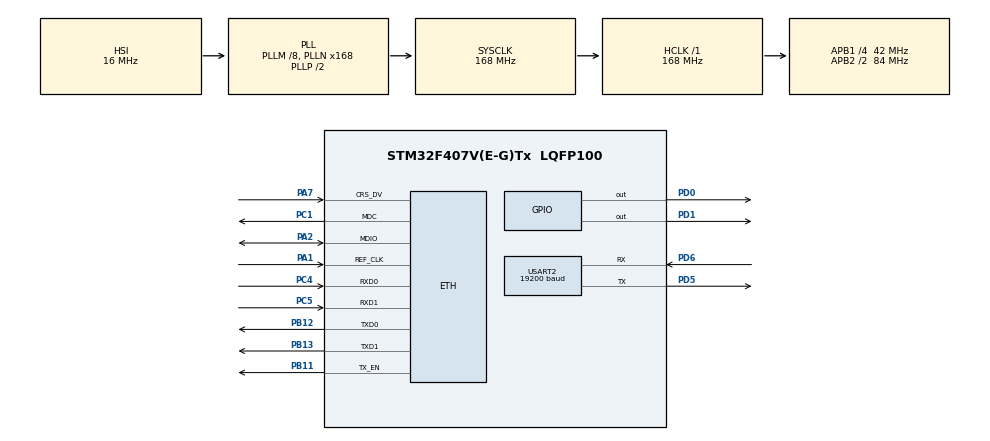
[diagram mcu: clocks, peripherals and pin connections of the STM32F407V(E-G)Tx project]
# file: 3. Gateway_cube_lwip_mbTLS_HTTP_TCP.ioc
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ETH.AutoNegotiation=ETH_AUTONEGOTIATION_DISABLE
ETH.MediaInterface=ETH_MEDIA_INTERFACE_RMII
FREERTOS.INCLUDE_pcTaskGetTaskName=1
FREERTOS.INCLUDE_xSemaphoreGetMutexHolder=1
FREERTOS.INCLUDE_xTaskAbortDelay=1
FREERTOS.INCLUDE_xTaskGetCurrentTaskHandle=1
FREERTOS.Tasks01=defaultTask,0,128,StartDefaultTask,Default,NULL
FREERTOS.configCHECK_FOR_STACK_OVERFLOW=0
FREERTOS.configUSE_MALLOC_FAILED_HOOK=1
LWIP.CHECKSUM_BY_HARDWARE=1
LWIP.GATEWAY_ADDRESS=192.168.002.001
LWIP.HTTPD_MAX_RETRIES=6
LWIP.HTTPD_SERVER_AGENT="RS485-ETH-WS-HVC"
LWIP.HTTPD_USE_CUSTOM_FSDATA=1
LWIP.IP_ADDRESS=192.168.002.020
LWIP.LWIP_DHCP=0
LWIP.LWIP_HTTPD=1
LWIP.LWIP_HTTPD_CGI=1
LWIP.LWIP_HTTPD_SSI=1
LWIP.LWIP_HTTPD_SUPPORT_POST=1
LWIP.MEM_SIZE=20000
LWIP.NETMASK_ADDRESS=255.255.255.000
LWIP.Version=v2.0.3_Cube
Mcu.Family=STM32F4
Mcu.Name=STM32F407V(E-G)Tx
Mcu.Package=LQFP100
NVIC.ETH_IRQn=true\:5\:0\:false\:false\:true\:true\:false
NVIC.PriorityGroup=NVIC_PRIORITYGROUP_4
NVIC.TIM6_DAC_IRQn=true\:0\:0\:false\:false\:true\:false\:false
NVIC.TimeBase=TIM6_DAC_IRQn
NVIC.TimeBaseIP=TIM6
NVIC.USART2_IRQn=true\:5\:0\:false\:false\:true\:true\:true
PA1.Mode=RMII
PA1.Signal=ETH_REF_CLK
PA13.Mode=Serial_Wire
PA13.Signal=SYS_JTMS-SWDIO
PA14.Mode=Serial_Wire
PA14.Signal=SYS_JTCK-SWCLK
PA2.Mode=RMII
PA2.Signal=ETH_MDIO
PA7.Mode=RMII
PA7.Signal=ETH_CRS_DV
PB11.Mode=RMII
PB11.Signal=ETH_TX_EN
PB12.Mode=RMII
PB12.Signal=ETH_TXD0
PB13.Mode=RMII
PB13.Signal=ETH_TXD1
PC1.Mode=RMII
PC1.Signal=ETH_MDC
PC4.Mode=RMII
PC4.Signal=ETH_RXD0
PC5.Mode=RMII
PC5.Signal=ETH_RXD1
PD0.Signal=GPIO_Output
PD1.Signal=GPIO_Output
PD5.Mode=Asynchronous
PD5.Signal=USART2_TX
PD6.Mode=Asynchronous
PD6.Signal=USART2_RX
PH0-OSC_IN.Mode=HSE-External-Oscillator
PH0-OSC_IN.Signal=RCC_OSC_IN
PH1-OSC_OUT.Mode=HSE-External-Oscillator
PH1-OSC_OUT.Signal=RCC_OSC_OUT
ProjectManager.HeapSize=0x200
ProjectManager.StackSize=0x400
ProjectManager.TargetToolchain=MDK-ARM V5
RCC.48MHZClocksFreq_Value=48000000
RCC.AHBFreq_Value=168000000
RCC.APB1CLKDivider=RCC_HCLK_DIV4
RCC.APB1Freq_Value=42000000
RCC.APB1TimFreq_Value=84000000
RCC.APB2CLKDivider=RCC_HCLK_DIV2
RCC.APB2Freq_Value=84000000
RCC.APB2TimFreq_Value=168000000
RCC.CortexFreq_Value=168000000
RCC.HCLKFreq_Value=168000000
RCC.HSE_VALUE=8000000
RCC.HSI_VALUE=16000000
RCC.LSE_VALUE=32768
RCC.PLLM=8
RCC.PLLN=168
RCC.PLLQ=7
RCC.SYSCLKFreq_VALUE=168000000
RCC.SYSCLKSource=RCC_SYSCLKSOURCE_PLLCLK
RCC.VCOOutputFreq_Value=336000000
USART2.BaudRate=19200
USART2.VirtualMode=VM_ASYNC
VP_CRC_VS_CRC.Mode=CRC_Activate
VP_FREERTOS_VS_ENABLE.Mode=Enabled
VP_LWIP_VS_Enabled.Mode=Enabled
VP_MBEDTLS_VS_MBEDTLS.Mode=Enabled
VP_RNG_VS_RNG.Mode=RNG_Activate
VP_SYS_VS_tim6.Mode=TIM6
board=custom

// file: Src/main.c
/* USER CODE BEGIN Header */
/**
  ******************************************************************************
  * @file           : main.c
  * @brief          : Main program body
  ******************************************************************************
  * This notice applies to any and all portions of this file
  * that are not between comment pairs USER CODE BEGIN and
  * USER CODE END. Other portions of this file, whether
  * inserted by the user or by software development tools
  * are owned by their respective copyright owners.
  *
  * Copyright (c) 2020 STMicroelectronics International N.V.
  * All rights reserved.
  *
  * Redistribution and use in source and binary forms, with or without
  * modification, are permitted, provided that the following conditions are met:
  *
  * 1. Redistribution of source code must retain the above copyright notice,
  *    this list of conditions and the following disclaimer.
  * 2. Redistributions in binary form must reproduce the above copyright notice,
  *    this list of conditions and the following disclaimer in the documentation
  *    and/or other materials provided with the distribution.
  * 3. Neither the name of STMicroelectronics nor the names of other
  *    contributors to this software may be used to endorse or promote products
  *    derived from this software without specific written permission.
  * 4. This software, including modifications and/or derivative works of this
  *    software, must execute solely and exclusively on microcontroller or
  *    microprocessor devices manufactured by or for STMicroelectronics.
  * 5. Redistribution and use of this software other than as permitted under
  *    this license is void and will automatically terminate your rights under
  *    this license.
  *
  * THIS SOFTWARE IS PROVIDED BY STMICROELECTRONICS AND CONTRIBUTORS "AS IS"
  * AND ANY EXPRESS, IMPLIED OR STATUTORY WARRANTIES, INCLUDING, BUT NOT
  * LIMITED TO, THE IMPLIED WARRANTIES OF MERCHANTABILITY, FITNESS FOR A
  * PARTICULAR PURPOSE AND NON-INFRINGEMENT OF THIRD PARTY INTELLECTUAL PROPERTY
  * RIGHTS ARE DISCLAIMED TO THE FULLEST EXTENT PERMITTED BY LAW. IN NO EVENT
  * SHALL STMICROELECTRONICS OR CONTRIBUTORS BE LIABLE FOR ANY DIRECT, INDIRECT,
  * INCIDENTAL, SPECIAL, EXEMPLARY, OR CONSEQUENTIAL DAMAGES (INCLUDING, BUT NOT
  * LIMITED TO, PROCUREMENT OF SUBSTITUTE GOODS OR SERVICES; LOSS OF USE, DATA,
  * OR PROFITS; OR BUSINESS INTERRUPTION) HOWEVER CAUSED AND ON ANY THEORY OF
  * LIABILITY, WHETHER IN CONTRACT, STRICT LIABILITY, OR TORT (INCLUDING
  * NEGLIGENCE OR OTHERWISE) ARISING IN ANY WAY OUT OF THE USE OF THIS SOFTWARE,
  * EVEN IF ADVISED OF THE POSSIBILITY OF SUCH DAMAGE.
  *
  ******************************************************************************
  */
/* USER CODE END Header */

#include "main.h"
#include "cmsis_os.h"
#include "mbedtls.h"
#include "app_config.h"

/* USER CODE BEGIN PTD */
void Led_Handler(void const * para);
/* USER CODE END PTD */

CRC_HandleTypeDef hcrc;

RNG_HandleTypeDef hrng;

UART_HandleTypeDef huart2;

osThreadId defaultTaskHandle;

void SystemClock_Config(void);
static void MX_GPIO_Init(void);
void MX_RNG_Init(void);
void MX_CRC_Init(void);
void MX_USART2_UART_Init(void);
void StartDefaultTask(void const * argument);

int main(void)
{

  /* MCU Configuration--------------------------------------------------------*/

  /* Reset of all peripherals, Initializes the Flash interface and the Systick. */
  HAL_Init();

  /* Configure the system clock */
  SystemClock_Config();

  /* Initialize all configured peripherals */
  MX_GPIO_Init();
  MX_RNG_Init();
  MX_CRC_Init();
  MX_USART2_UART_Init();
  /* USER CODE BEGIN 2 */

	printf("\r\nStart");

  /* USER CODE END 2 */

  /* Create the thread(s) */
  /* definition and creation of defaultTask */
  osThreadDef(defaultTask, StartDefaultTask, osPriorityNormal, 0, configMINIMAL_STACK_SIZE);
  defaultTaskHandle = osThreadCreate(osThread(defaultTask), NULL);

  /* Start scheduler */
  osKernelStart();

  /* We should never get here as control is now taken by the scheduler */

  /* Infinite loop */
  while (1)
  {

  }
}

void SystemClock_Config(void)
{
  RCC_OscInitTypeDef RCC_OscInitStruct = {0};
  RCC_ClkInitTypeDef RCC_ClkInitStruct = {0};

  /**Configure the main internal regulator output voltage
  */
  __HAL_RCC_PWR_CLK_ENABLE();
  __HAL_PWR_VOLTAGESCALING_CONFIG(PWR_REGULATOR_VOLTAGE_SCALE1);
  /**Initializes the CPU, AHB and APB busses clocks
  */
  RCC_OscInitStruct.OscillatorType = RCC_OSCILLATORTYPE_HSI;
  RCC_OscInitStruct.HSIState = RCC_HSI_ON;
  RCC_OscInitStruct.HSICalibrationValue = RCC_HSICALIBRATION_DEFAULT;
  RCC_OscInitStruct.PLL.PLLState = RCC_PLL_ON;
  RCC_OscInitStruct.PLL.PLLSource = RCC_PLLSOURCE_HSI;
  RCC_OscInitStruct.PLL.PLLM = 8;
  RCC_OscInitStruct.PLL.PLLN = 168;
  RCC_OscInitStruct.PLL.PLLP = RCC_PLLP_DIV2;
  RCC_OscInitStruct.PLL.PLLQ = 7;
  if (HAL_RCC_OscConfig(&RCC_OscInitStruct) != HAL_OK)
  {
    Error_Handler();
  }
  /**Initializes the CPU, AHB and APB busses clocks
  */
  RCC_ClkInitStruct.ClockType = RCC_CLOCKTYPE_HCLK|RCC_CLOCKTYPE_SYSCLK
                              |RCC_CLOCKTYPE_PCLK1|RCC_CLOCKTYPE_PCLK2;
  RCC_ClkInitStruct.SYSCLKSource = RCC_SYSCLKSOURCE_PLLCLK;
  RCC_ClkInitStruct.AHBCLKDivider = RCC_SYSCLK_DIV1;
  RCC_ClkInitStruct.APB1CLKDivider = RCC_HCLK_DIV4;
  RCC_ClkInitStruct.APB2CLKDivider = RCC_HCLK_DIV2;

  if (HAL_RCC_ClockConfig(&RCC_ClkInitStruct, FLASH_LATENCY_5) != HAL_OK)
  {
    Error_Handler();
  }
}

void MX_CRC_Init(void)
{

  hcrc.Instance = CRC;
  if (HAL_CRC_Init(&hcrc) != HAL_OK)
  {
    Error_Handler();
  }

}

void MX_RNG_Init(void)
{

  hrng.Instance = RNG;
  if (HAL_RNG_Init(&hrng) != HAL_OK)
  {
    Error_Handler();
  }

}

void MX_USART2_UART_Init(void)
{

  huart2.Instance = USART2;
  huart2.Init.BaudRate = 19200;
  huart2.Init.WordLength = UART_WORDLENGTH_8B;
  huart2.Init.StopBits = UART_STOPBITS_1;
  huart2.Init.Parity = UART_PARITY_NONE;
  huart2.Init.Mode = UART_MODE_TX_RX;
  huart2.Init.HwFlowCtl = UART_HWCONTROL_NONE;
  huart2.Init.OverSampling = UART_OVERSAMPLING_16;
  if (HAL_UART_Init(&huart2) != HAL_OK)
  {
    Error_Handler();
  }

}
//

static void MX_GPIO_Init(void)
{
  GPIO_InitTypeDef GPIO_InitStruct = {0};

  /* GPIO Ports Clock Enable */
  __HAL_RCC_GPIOH_CLK_ENABLE();
  __HAL_RCC_GPIOC_CLK_ENABLE();
  __HAL_RCC_GPIOA_CLK_ENABLE();
  __HAL_RCC_GPIOB_CLK_ENABLE();
  __HAL_RCC_GPIOD_CLK_ENABLE();

  /*Configure GPIO pin Output Level */
  HAL_GPIO_WritePin(GPIOD, GPIO_PIN_0|GPIO_PIN_1, GPIO_PIN_RESET);

  /*Configure GPIO pins : PD0 PD1 */
  GPIO_InitStruct.Pin = GPIO_PIN_0|GPIO_PIN_1;
  GPIO_InitStruct.Mode = GPIO_MODE_OUTPUT_PP;
  GPIO_InitStruct.Pull = GPIO_NOPULL;
  GPIO_InitStruct.Speed = GPIO_SPEED_FREQ_LOW;
  HAL_GPIO_Init(GPIOD, &GPIO_InitStruct);

}

void StartDefaultTask(void const * argument)
{
  /* MX_LWIP_Init() is generated within mbedtls_net_init() function in net_cockets.c file */
  /* Up to user to call mbedtls_net_init() function in MBEDTLS initialization step */

  /* Up to user define the empty MX_MBEDTLS_Init() function located in mbedtls.c file */
  MX_MBEDTLS_Init();

	osThreadDef(LedThread, Led_Handler, osPriorityLow, 0, 16);
  osThreadCreate (osThread(LedThread), NULL);

	osThreadDef(Server, SSL_Server, osPriorityHigh, 0, configMINIMAL_STACK_SIZE*20);
  osThreadCreate (osThread(Server), NULL);

  /* USER CODE BEGIN 5 */
  /* Infinite loop */
  for(;;)
  {
    osDelay(500);
		//printf("Hello\r\n");
  }
  /* USER CODE END 5 */
}
//

void HAL_TIM_PeriodElapsedCallback(TIM_HandleTypeDef *htim)
{
  if (htim->Instance == TIM6) {
    HAL_IncTick();
  }
}

void Error_Handler(void)
{
}

/************************ (C) COPYRIGHT STMicroelectronics *****END OF FILE****/

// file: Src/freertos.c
/* USER CODE BEGIN Header */
/**
  ******************************************************************************
  * File Name          : freertos.c
  * Description        : Code for freertos applications
  ******************************************************************************
  * This notice applies to any and all portions of this file
  * that are not between comment pairs USER CODE BEGIN and
  * USER CODE END. Other portions of this file, whether
  * inserted by the user or by software development tools
  * are owned by their respective copyright owners.
  *
  * Copyright (c) 2020 STMicroelectronics International N.V.
  * All rights reserved.
  *
  * Redistribution and use in source and binary forms, with or without
  * modification, are permitted, provided that the following conditions are met:
  *
  * 1. Redistribution of source code must retain the above copyright notice,
  *    this list of conditions and the following disclaimer.
  * 2. Redistributions in binary form must reproduce the above copyright notice,
  *    this list of conditions and the following disclaimer in the documentation
  *    and/or other materials provided with the distribution.
  * 3. Neither the name of STMicroelectronics nor the names of other
  *    contributors to this software may be used to endorse or promote products
  *    derived from this software without specific written permission.
  * 4. This software, including modifications and/or derivative works of this
  *    software, must execute solely and exclusively on microcontroller or
  *    microprocessor devices manufactured by or for STMicroelectronics.
  * 5. Redistribution and use of this software other than as permitted under
  *    this license is void and will automatically terminate your rights under
  *    this license.
  *
  * THIS SOFTWARE IS PROVIDED BY STMICROELECTRONICS AND CONTRIBUTORS "AS IS"
  * AND ANY EXPRESS, IMPLIED OR STATUTORY WARRANTIES, INCLUDING, BUT NOT
  * LIMITED TO, THE IMPLIED WARRANTIES OF MERCHANTABILITY, FITNESS FOR A
  * PARTICULAR PURPOSE AND NON-INFRINGEMENT OF THIRD PARTY INTELLECTUAL PROPERTY
  * RIGHTS ARE DISCLAIMED TO THE FULLEST EXTENT PERMITTED BY LAW. IN NO EVENT
  * SHALL STMICROELECTRONICS OR CONTRIBUTORS BE LIABLE FOR ANY DIRECT, INDIRECT,
  * INCIDENTAL, SPECIAL, EXEMPLARY, OR CONSEQUENTIAL DAMAGES (INCLUDING, BUT NOT
  * LIMITED TO, PROCUREMENT OF SUBSTITUTE GOODS OR SERVICES; LOSS OF USE, DATA,
  * OR PROFITS; OR BUSINESS INTERRUPTION) HOWEVER CAUSED AND ON ANY THEORY OF
  * LIABILITY, WHETHER IN CONTRACT, STRICT LIABILITY, OR TORT (INCLUDING
  * NEGLIGENCE OR OTHERWISE) ARISING IN ANY WAY OUT OF THE USE OF THIS SOFTWARE,
  * EVEN IF ADVISED OF THE POSSIBILITY OF SUCH DAMAGE.
  *
  ******************************************************************************
  */
/* USER CODE END Header */

#include "FreeRTOS.h"
#include "task.h"
#include "main.h"

/* Hook prototypes */
void vApplicationMallocFailedHook(void);

/* USER CODE BEGIN 5 */
__weak void vApplicationMallocFailedHook(void)
{
   /* vApplicationMallocFailedHook() will only be called if
   configUSE_MALLOC_FAILED_HOOK is set to 1 in FreeRTOSConfig.h. It is a hook
   function that will get called if a call to pvPortMalloc() fails.
   pvPortMalloc() is called internally by the kernel whenever a task, queue,
   timer or semaphore is created. It is also called by various parts of the
   demo application. If heap_1.c or heap_2.c are used, then the size of the
   heap available to pvPortMalloc() is defined by configTOTAL_HEAP_SIZE in
   FreeRTOSConfig.h, and the xPortGetFreeHeapSize() API function can be used
   to query the size of free heap space that remains (although it does not
   provide information on how the remaining heap might be fragmented). */
}
/* USER CODE END 5 */

/************************ (C) COPYRIGHT STMicroelectronics *****END OF FILE****/
